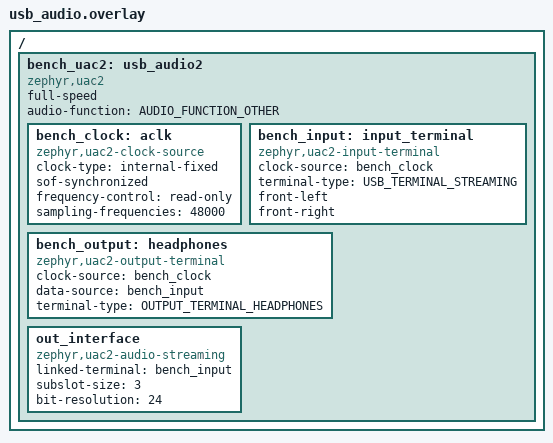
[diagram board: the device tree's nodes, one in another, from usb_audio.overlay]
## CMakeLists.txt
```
cmake_minimum_required(VERSION 3.20.0)
set(CMAKE_OBJECT_PATH_MAX 240)
find_package(Zephyr REQUIRED HINTS $ENV{ZEPHYR_BASE})
project(benchmark)
set(BENCH_ROLE tx CACHE STRING "tx, tx54 or rx")
set(BENCH_CODEC etsi CACHE STRING "etsi or google")
set(BENCH_FRAMES 200 CACHE STRING "Frames per case")
set(BENCH_SOAK_FRAMES 0 CACHE STRING "Frames per transport soak case")
set(BENCH_BITRATE 320000 CACHE STRING "Total stereo bitrate")
set(BENCH_PCM_BITS 16 CACHE STRING "LC3plus input precision; Opus sweeps 16 and 24")
set(BENCH_ASYNC_ONLY 0 CACHE STRING "Run nRF54 buffered radio cases only")
set(BENCH_USB 0 CACHE STRING "Receive PCM through USB Audio Class")
set(BENCH_OPTIMIZATIONS 0 CACHE STRING "Optimization experiment bit mask")
zephyr_get(BENCH_ROLE SYSBUILD)
zephyr_get(BENCH_CODEC SYSBUILD)
zephyr_get(BENCH_FRAMES SYSBUILD)
zephyr_get(BENCH_SOAK_FRAMES SYSBUILD)
zephyr_get(BENCH_BITRATE SYSBUILD)
zephyr_get(BENCH_PCM_BITS SYSBUILD)
zephyr_get(BENCH_ASYNC_ONLY SYSBUILD)
zephyr_get(BENCH_USB SYSBUILD)
zephyr_get(BENCH_OPTIMIZATIONS SYSBUILD)
target_compile_definitions(app PRIVATE BENCH_OPTIMIZATIONS=${BENCH_OPTIMIZATIONS})
math(EXPR BENCH_LEAN "${BENCH_OPTIMIZATIONS} & 1")
message(STATUS "Bench codec=${BENCH_CODEC} frames=${BENCH_FRAMES} soak=${BENCH_SOAK_FRAMES} bitrate=${BENCH_BITRATE} pcm_bits=${BENCH_PCM_BITS} LTO=${CONFIG_LTO}")
if(BENCH_CODEC MATCHES "-lto$" AND NOT CONFIG_LTO)
  message(FATAL_ERROR "Requested LTO was not enabled by Kconfig")
endif()
target_sources(app PRIVATE src/radio.c)
if(BENCH_USB)
  if(NOT BENCH_ROLE STREQUAL "tx" OR NOT BENCH_CODEC STREQUAL "google-custom-lto")
    message(FATAL_ERROR "USB benchmark requires tx/google-custom-lto")
  endif()
  target_sources(app PRIVATE src/main_usb.c src/usb_pcm.c src/usb_crc.c)
  target_compile_definitions(app PRIVATE BENCH_USB=1)
else()
  target_sources(app PRIVATE src/main.c)
endif()
target_compile_definitions(app PRIVATE BENCH_FRAMES=${BENCH_FRAMES} BENCH_SOAK_FRAMES=${BENCH_SOAK_FRAMES}
  BENCH_BITRATE=${BENCH_BITRATE} BENCH_PCM_BITS=${BENCH_PCM_BITS} BENCH_ASYNC_ONLY=${BENCH_ASYNC_ONLY})
if(BENCH_ROLE MATCHES "^tx")
  target_compile_definitions(app PRIVATE BENCH_TX=1)
  if(BENCH_ROLE STREQUAL "tx54")
    if(NOT BENCH_CODEC STREQUAL "google-lto")
      message(FATAL_ERROR "The tx54 benchmark currently supports google-lto")
    endif()
    target_compile_definitions(app PRIVATE BENCH_NRF54=1 BENCH_HAS_ASYNC=1)
    target_sources(app PRIVATE src/radio_async.c)
  endif()
  if(BENCH_CODEC MATCHES "^opus")
    include(opus.cmake)
  elseif(BENCH_CODEC MATCHES "^sbc")
    include(sbc.cmake)
  elseif(BENCH_CODEC MATCHES "^wavpack")
    include(wavpack.cmake)
  else()
    target_sources(app PRIVATE src/codec.c)
  endif()
  if(BENCH_CODEC MATCHES "^(opus|sbc|wavpack)")
    # Source list, precision and Cortex-M4 DSP options are in opus.cmake.
  elseif(BENCH_CODEC MATCHES "^etsi")
    set(REF ${CMAKE_CURRENT_SOURCE_DIR}/../third_party/lc3plus/fixed_point)
    file(GLOB CODEC_SOURCES ${REF}/*.c ${REF}/basic_op/*.c)
    list(FILTER CODEC_SOURCES EXCLUDE REGEX "/(codec_exe|ccConvert)\\.c$")
    # The desktop reference puts a 200 kB dummy scratch array on the stack.
    # Reuse our statically allocated scratch area during initialization.
    # This changes storage only; the codec arithmetic is unchanged.
    list(REMOVE_ITEM CODEC_SOURCES ${REF}/lc3plus.c)
    file(READ ${REF}/lc3plus.c PORTED_SOURCE)
    string(REPLACE "UWord8 tmp_scratch[LC3PLUS_ENC_MAX_USER_SYSTEM_SCRATCH_SIZE];"
      "extern unsigned char bench_codec_scratch[]; UWord8 *tmp_scratch = bench_codec_scratch;"
      PORTED_SOURCE "${PORTED_SOURCE}")
    file(WRITE ${CMAKE_CURRENT_BINARY_DIR}/lc3plus_port.c "${PORTED_SOURCE}")
    list(APPEND CODEC_SOURCES ${CMAKE_CURRENT_BINARY_DIR}/lc3plus_port.c)
    target_sources(app PRIVATE ${CODEC_SOURCES})
    target_sources(app PRIVATE src/ref_port.c)
    target_include_directories(app PRIVATE ${REF} ${REF}/basic_op)
    target_compile_definitions(app PRIVATE CODEC_ETSI=1 SUBSET_ALL DISABLE_HR_MODE WMOPS=0 DONT_COUNT_MEM NO_SCRATCH_STATS NDEBUG)
  else()
    set(REF ${CMAKE_CURRENT_SOURCE_DIR}/../third_party/liblc3)
    file(GLOB CODEC_SOURCES ${REF}/src/*.c)
    if(BENCH_CODEC STREQUAL "google-custom-lto")
      set(CUSTOM_DIR ${CMAKE_CURRENT_BINARY_DIR}/lc3-custom)
      set_property(DIRECTORY APPEND PROPERTY CMAKE_CONFIGURE_DEPENDS
        ${CMAKE_CURRENT_SOURCE_DIR}/../../tools/prepare-lc3-custom.py
        ${CMAKE_CURRENT_SOURCE_DIR}/../../tools/prepare-lc3-lite.py
        ${CMAKE_CURRENT_SOURCE_DIR}/src/custom_sns.inc
        ${CMAKE_CURRENT_SOURCE_DIR}/src/custom_spec.inc)
      execute_process(COMMAND ${PYTHON_EXECUTABLE}
        ${CMAKE_CURRENT_SOURCE_DIR}/../../tools/prepare-lc3-custom.py
        --source ${REF}/src --output ${CUSTOM_DIR}
        COMMAND_ERROR_IS_FATAL ANY)
      file(GLOB CODEC_SOURCES ${CUSTOM_DIR}/*.c)
      target_sources(app PRIVATE src/lc3_lite.c src/lc3_custom.c src/radio_async.c)
      target_include_directories(app PRIVATE src ${CUSTOM_DIR})
      target_compile_definitions(app PRIVATE CODEC_LC3_CUSTOM=1 CODEC_LC3_LITE=1 BENCH_HAS_ASYNC=1)
      if(NOT BENCH_LEAN)
        target_compile_definitions(app PRIVATE LC3_LITE_PROFILE=1)
      endif()
    elseif(BENCH_CODEC STREQUAL "google-lite-lto")
      set(LITE_DIR ${CMAKE_CURRENT_BINARY_DIR}/lc3-lite)
      set_property(DIRECTORY APPEND PROPERTY CMAKE_CONFIGURE_DEPENDS
        ${CMAKE_CURRENT_SOURCE_DIR}/../../tools/prepare-lc3-lite.py
        ${REF}/src/lc3.c ${REF}/src/tns.c ${REF}/src/spec.c)
      execute_process(COMMAND ${PYTHON_EXECUTABLE}
        ${CMAKE_CURRENT_SOURCE_DIR}/../../tools/prepare-lc3-lite.py
        --source ${REF}/src --output ${LITE_DIR}
        COMMAND_ERROR_IS_FATAL ANY)
      foreach(unit lc3 tns spec)
        list(REMOVE_ITEM CODEC_SOURCES ${REF}/src/${unit}.c)
        list(APPEND CODEC_SOURCES ${LITE_DIR}/${unit}.c)
      endforeach()
      target_sources(app PRIVATE src/lc3_lite.c src/radio_async.c)
      target_include_directories(app PRIVATE src ${REF}/src)
      target_compile_definitions(app PRIVATE CODEC_LC3_LITE=1 LC3_LITE_PROFILE=1 BENCH_HAS_ASYNC=1)
    endif()
    target_sources(app PRIVATE ${CODEC_SOURCES})
    target_include_directories(app PRIVATE ${REF}/include)
    target_compile_definitions(app PRIVATE LC3_PLUS=1 LC3_PLUS_HR=1)
  endif()
  set_source_files_properties(${CODEC_SOURCES} src/codec.c src/codec_opus.c src/codec_sbc.c src/codec_wavpack.c PROPERTIES COMPILE_OPTIONS "-O3;-std=c11")
  if(BENCH_CODEC MATCHES "^google.*-lto$")
    set_property(SOURCE ${CODEC_SOURCES} APPEND PROPERTY COMPILE_OPTIONS -ffast-math)
  endif()
  if(BENCH_CODEC STREQUAL "google-custom-lto")
    # Experiment with static-loop expansion in the existing transform kernel.
    # Retain the transform, window and coefficient tables.
    set_property(SOURCE ${CUSTOM_DIR}/mdct.c APPEND PROPERTY COMPILE_OPTIONS -funroll-loops)
  endif()
  target_link_libraries(app PRIVATE m)
elseif(BENCH_ROLE STREQUAL "rx")
  target_sources(app PRIVATE src/rx_ipc.c)
  target_compile_definitions(app PRIVATE BENCH_RX=1)
endif()
```

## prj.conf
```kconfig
CONFIG_ESB=y
CONFIG_ESB_MAX_PAYLOAD_LENGTH=252
CONFIG_ESB_TX_FIFO_SIZE=8
CONFIG_ESB_RX_FIFO_SIZE=16
CONFIG_CLOCK_CONTROL=y
CONFIG_USE_SEGGER_RTT=y
CONFIG_RTT_CONSOLE=y
CONFIG_UART_CONSOLE=n
CONFIG_SERIAL=n
CONFIG_CONSOLE=y
CONFIG_PRINTK=y
CONFIG_LOG=n
CONFIG_SEGGER_RTT_BUFFER_SIZE_UP=16384
CONFIG_SEGGER_RTT_INIT_MODE_ALWAYS=y
CONFIG_SEGGER_RTT_MODE_NO_BLOCK_SKIP=y
CONFIG_MAIN_STACK_SIZE=16384
CONFIG_SYSTEM_WORKQUEUE_STACK_SIZE=2048
CONFIG_SPEED_OPTIMIZATIONS=y
CONFIG_MINIMAL_LIBC=y
CONFIG_FPU=y
CONFIG_ASSERT=y
CONFIG_THREAD_STACK_INFO=y
CONFIG_INIT_STACKS=y
CONFIG_HW_STACK_PROTECTION=y
CONFIG_BOOT_BANNER=n
CONFIG_CRC=y

# The nRF5340 PRX forwards complete LC3-fast frames to the application core.
# The network-core RADIO/ESB ACK path remains independent of the decoder.
CONFIG_IPC_SERVICE=y
CONFIG_IPC_SERVICE_BACKEND_RPMSG=y
CONFIG_IPC_SERVICE_BACKEND_RPMSG_WQ_STACK_SIZE=2048
CONFIG_MBOX=y
CONFIG_HEAP_MEM_POOL_SIZE=2048
```

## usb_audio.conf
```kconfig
CONFIG_USB_DEVICE_STACK_NEXT=y
CONFIG_USBD_AUDIO2_CLASS=y
CONFIG_USBD_THREAD_STACK_SIZE=2048
CONFIG_UDC_NRF_THREAD_STACK_SIZE=1024
CONFIG_USBD_MAX_UDC_MSG=32
# Nano libc uses a byte-at-a-time memcpy on this toolchain. USB and the
# message/radio queues benefit from the full library's optimized copy routine.
CONFIG_NEWLIB_LIBC_NANO=n
```

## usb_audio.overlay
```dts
#include <dt-bindings/usb/audio.h>
/ {
    bench_uac2: usb_audio2 {
        compatible = "zephyr,uac2";
        status = "okay";
        full-speed;
        audio-function = <AUDIO_FUNCTION_OTHER>;
        bench_clock: aclk {
            compatible = "zephyr,uac2-clock-source";
            clock-type = "internal-fixed";
            sof-synchronized;
            frequency-control = "read-only";
            sampling-frequencies = <48000>;
        };
        bench_input: input_terminal {
            compatible = "zephyr,uac2-input-terminal";
            clock-source = <&bench_clock>;
            terminal-type = <USB_TERMINAL_STREAMING>;
            front-left;
            front-right;
        };
        bench_output: headphones {
            compatible = "zephyr,uac2-output-terminal";
            clock-source = <&bench_clock>;
            data-source = <&bench_input>;
            terminal-type = <OUTPUT_TERMINAL_HEADPHONES>;
        };
        out_interface {
            compatible = "zephyr,uac2-audio-streaming";
            linked-terminal = <&bench_input>;
            subslot-size = <3>;
            bit-resolution = <24>;
        };
    };
};
```

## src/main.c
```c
#include "bench.h"
#include <string.h>
#include <zephyr/sys/crc.h>
#include <cmsis_core.h>
#ifdef BENCH_RX
#include "rx_ipc.h"
#endif
#ifdef CODEC_LC3_LITE
#include "lc3_lite.h"
#endif
#ifdef CODEC_LC3_CUSTOM
#include "lc3_custom.h"
#endif
#ifdef BENCH_TX
static uint8_t encoded[MAX_FRAME];
static uint32_t timings[1024];
#ifdef CODEC_LC3_CUSTOM
static uint8_t vector_data[4][204];
static unsigned vector_bytes[4];
#endif
static uint32_t cycles_to_us(uint64_t cycles)
{
    return (uint32_t)(cycles * 1000000u / SystemCoreClock);
}
static int send_frame(uint32_t run, uint32_t seq, unsigned bytes,
                      bool async, uint64_t ready_us, uint64_t deadline_us)
{
    uint32_t crc = crc32_ieee(encoded, bytes);
    for (unsigned off=0; off<bytes; off+=CHUNK) {
        uint8_t packet[252];
        struct header h = {MAGIC, run, seq, crc, bytes, off, DATA, {0}};
        unsigned n = MIN(CHUNK, bytes-off);
        memcpy(packet, &h, sizeof(h)); memcpy(packet+sizeof(h), encoded+off, n);
        int rc;
#ifdef BENCH_HAS_ASYNC
        if (async) rc = radio_async_submit(packet, sizeof(h)+n, ready_us, deadline_us);
        else
#endif
            rc = radio_send(packet, sizeof(h)+n);
        if (rc) return rc;
    }
    return 0;
}
static void control(unsigned type, uint32_t run, uint32_t count)
{
    struct header h = {.magic=MAGIC, .run=run, .seq=count, .type=type};
    for (int i=0;i<3;i++) { if (!radio_send(&h, sizeof(h))) return; }
    printk("CONTROL_FAIL run=%u type=%u\n", run, type);
}
static void run_case(unsigned id, unsigned mode, unsigned frame_us, unsigned bitrate, unsigned nframes)
{
    /* mode 0: local encoding, 1: sequential RF, 2: synthetic RF only,
     * mode 3: encoding with concurrent RF at a fixed source cadence. */
    if (mode != 2) {
        int rc = codec_init(frame_us, bitrate);
        if (rc) { printk("CONFIG_ERROR id=%u rc=%d\n", id, rc); return; }
    }
    printk("BEGIN id=%u mode=%u frame_us=%u bitrate=%u frames=%u\n", id, mode, frame_us, bitrate, nframes);
    if (mode) control(START, id, nframes);
#ifdef BENCH_HAS_ASYNC
    struct radio_async_stats async_stats = {0};
    if (mode == 3 && radio_async_reset()) {
        printk("ASYNC_RESET_ERROR id=%u\n", id);
        return;
    }
#endif
    uint32_t ok0=tx_ok, fail0=tx_fail, ret0=tx_retries;
    uint64_t cycles=0, work=0, start=now_us(), due=start;
    uint64_t payload_bytes=0, slots=0;
    uint32_t payload_min=UINT32_MAX, payload_max=0, fragmented=0, data_packets=0;
#ifdef CODEC_SBC
    const unsigned period_num=8000, period_den=3;
#else
    const unsigned period_num=frame_us, period_den=1;
#endif
    uint32_t worst=0, worst_work=0, late=0, errors=0, send_errors=0, skips=0, timing_errors=0;
    uint64_t api_cycles=0;
    uint32_t api_max=0;
    uint32_t release_late_max=0;
    for (unsigned seq=0; seq<nframes; seq++) {
        uint64_t release=start+(uint64_t)seq*period_num/period_den;
        if (mode == 3) {
            uint64_t now=now_us();
            if (now<release) k_sleep(K_USEC(release-now));
            now=now_us();
            release_late_max=MAX(release_late_max,now>release ? now-release : 0);
        }
        unsigned bytes = bitrate*(uint64_t)frame_us/8000000;
        uint64_t t0=now_us();
        /* J-Link may clear trace enable on detach. Re-arm each measurement and
         * reject a case if a mid-frame probe change invalidates its counter. */
        CoreDebug->DEMCR |= CoreDebug_DEMCR_TRCENA_Msk;
        DWT->CTRL |= DWT_CTRL_CYCCNTENA_Msk;
        uint32_t c0=DWT->CYCCNT;
        if (mode != 2) {
            if (codec_encode(seq, encoded, &bytes)) errors++;
        } else {
            for (unsigned i=0;i<bytes;i++) encoded[i]=(uint8_t)(seq+i*29);
        }
        uint32_t dc=DWT->CYCCNT-c0;
        uint32_t measured_us=now_us()-t0;
        uint32_t cycle_us=cycles_to_us(dc);
        if (!dc || cycle_us+200<measured_us || measured_us+200<cycle_us) timing_errors++;
        if (mode != 2) { api_cycles+=codec_api_cycles; api_max=MAX(api_max,codec_api_cycles); }
        cycles+=dc; worst=MAX(worst, dc);
        payload_bytes+=bytes;
        payload_min=MIN(payload_min,bytes); payload_max=MAX(payload_max,bytes);
        fragmented+=bytes>CHUNK;
        data_packets+=DIV_ROUND_UP(bytes,CHUNK);
        if (seq<ARRAY_SIZE(timings)) timings[seq]=dc;
        /* Async ACK target: one further frame interval after the encode
         * deadline. Track its violations separately from producer cadence. */
        if (mode && send_frame(id,seq,bytes,mode==3,release,
                               release+2*period_num/period_den)) send_errors++;
#ifdef CODEC_LC3_CUSTOM
        if (seq<=75 && seq%25==0 && bytes<=204) {
            vector_bytes[seq/25]=bytes;
            memcpy(vector_data[seq/25],encoded,bytes);
        }
#endif
        uint32_t elapsed=now_us()-t0;
        work+=elapsed; worst_work=MAX(worst_work,elapsed);
        if (mode == 3) {
            due=start+(uint64_t)(seq+1)*period_num/period_den;
            if (now_us()>due) late++;
            /* Never shift the source phase or skip input to hide overload. */
        } else if (mode) {
            due=start+(++slots)*period_num/period_den;
            uint64_t now=now_us();
            if (now>due) {
                late++;
                /* Account for unsustainable source cadence; do not hide it
                 * by moving the next deadline forward without reporting. */
                while (start+(slots+1)*period_num/period_den<=now) { slots++; skips++; }
            } else k_sleep(K_USEC(due-now));
        }
    }
    uint64_t duration=now_us()-start;
#ifdef BENCH_HAS_ASYNC
    if (mode == 3) {
        int rc=radio_async_drain(&async_stats);
        if (rc) { printk("ASYNC_DRAIN_ERROR id=%u rc=%d\n",id,rc); return; }
        send_errors+=async_stats.errors;
        /* Include the last ACK; compare duration against nframes*period. */
        duration=now_us()-start;
    }
#endif
    if (mode) { control(END,id,nframes); k_sleep(K_MSEC(150)); }
    unsigned tcount=MIN(nframes, ARRAY_SIZE(timings));
    for(unsigned i=1;i<tcount;i++) { uint32_t x=timings[i]; unsigned j=i; while(j&&timings[j-1]>x){timings[j]=timings[j-1];j--;} timings[j]=x; }
    printk("RESULT id=%u mode=%u frame_us=%u bitrate=%u frames=%u enc_avg_us=%u enc_max_us=%u enc_p99_us=%u work_avg_us=%u work_max_us=%u late=%u skipped=%u codec_errors=%u send_errors=%u ack_ok=%u ack_fail=%u retries=%u elapsed_us=%llu",
       id,mode,frame_us,bitrate,nframes,cycles_to_us(cycles/nframes),cycles_to_us(worst),cycles_to_us(timings[(tcount-1)*99/100]),(uint32_t)(work/nframes),worst_work,late,skips,errors,send_errors,tx_ok-ok0,tx_fail-fail0,tx_retries-ret0,duration);
#ifdef CODEC_OPUS
    printk(" pcm_bits=%u complexity=%u",opus_pcm_bits,opus_complexity);
#else
    printk(" pcm_bits=%u",BENCH_PCM_BITS);
#endif
    printk(" api_avg_us=%u api_max_us=%u",cycles_to_us(api_cycles/nframes),cycles_to_us(api_max));
#ifdef CODEC_LC3_LITE
    printk(" lite_flags=%u",lc3_lite_flags);
#endif
#ifdef CODEC_LC3_CUSTOM
    printk(" sns_mode=%u rate_mode=%u tns=%u cap_channels=%u sns_clips=%u",
        custom_sns,custom_rate,custom_tns,custom_cap_frames,custom_sns_clips);
#endif
#ifdef CODEC_WAVPACK
    printk(" wavpack_fast=%u",wavpack_fast);
#endif
    printk(" timing_errors=%u payload_bytes=%llu period_num_us=%u period_den=%u",timing_errors,payload_bytes,period_num,period_den);
#ifdef BENCH_HAS_ASYNC
    if (mode == 3) printk(" radio_completed=%u radio_late=%u pending_peak=%u radio_service_avg_us=%u radio_service_max_us=%u ready_to_ack_avg_us=%u ready_to_ack_max_us=%u release_late_max_us=%u ack_budget_us=%u",
        async_stats.completed,async_stats.late,async_stats.peak_pending,
        (uint32_t)(async_stats.service_total_us/MAX(async_stats.completed,1)),async_stats.service_max_us,
        (uint32_t)(async_stats.latency_total_us/MAX(async_stats.completed,1)),async_stats.latency_max_us,
        release_late_max,2*period_num/period_den);
#endif
    printk(" payload_min=%u payload_max=%u fragmented_frames=%u data_packets=%u\n",payload_min,payload_max,fragmented,data_packets);
#ifdef CODEC_LC3_LITE
    /* Gain is nested inside spec; do not add it again to the stage total. */
    printk("PROFILE id=%u flags=%u",id,lc3_lite_flags);
    const char *names[] = {"attack","ltpf","mdct","energy","bw","sns","tns","spec","bits","gain"};
    for (unsigned i=0;i<PROF_COUNT;i++)
        printk(" %s_us=%u",names[i],cycles_to_us(lc3_lite_cycles[i]/nframes));
    printk("\n");
#endif
#ifdef CODEC_LC3_CUSTOM
    for (unsigned v=0;v<4 && v*25<nframes;v++) {
        printk("VECTOR id=%u seq=%u bytes=%u data=",id,v*25,vector_bytes[v]);
        for (unsigned b=0;b<vector_bytes[v];b++) printk("%02x",vector_data[v][b]);
        printk("\n");
    }
#endif
}
int main(void)
{
    CoreDebug->DEMCR |= CoreDebug_DEMCR_TRCENA_Msk;
    DWT->CYCCNT=0; DWT->CTRL |= DWT_CTRL_CYCCNTENA_Msk;
    int rc=radio_init();
    printk("BOOT TX codec=%s lto=%u cpu_hz=%u radio_init=%d frames=%u\n",codec_name(),IS_ENABLED(CONFIG_LTO),SystemCoreClock,rc,BENCH_FRAMES);
    if(rc) return rc;
    k_sleep(K_SECONDS(10));
    unsigned id=0;
#ifdef BENCH_NRF54
    const unsigned rates[] = {256000,320000};
#if BENCH_ASYNC_ONLY
    id=100;
    for (unsigned r=0;r<ARRAY_SIZE(rates);r++)
        run_case(++id,3,2500,rates[r],BENCH_FRAMES);
    if (BENCH_SOAK_FRAMES)
        for (unsigned r=0;r<ARRAY_SIZE(rates);r++)
            run_case(++id,3,2500,rates[r],BENCH_SOAK_FRAMES);
#else
    const unsigned frame_periods[] = {10000,5000,2500};
    for (unsigned r=0;r<ARRAY_SIZE(rates);r++)
        for (unsigned mode=0;mode<=1;mode++)
            for (unsigned f=0;f<ARRAY_SIZE(frame_periods);f++)
                run_case(++id,mode,frame_periods[f],rates[r],BENCH_FRAMES);
    if (BENCH_SOAK_FRAMES)
        for (unsigned r=0;r<ARRAY_SIZE(rates);r++)
            run_case(++id,1,2500,rates[r],BENCH_SOAK_FRAMES);
#endif
#elif defined(CODEC_LC3_CUSTOM)
    const unsigned rates[] = {256000,320000,400000,480000};
    const unsigned configs[][3] = {
        {0,0,1}, {1,0,1}, {2,0,1}, {3,0,1},
        {1,1,1}, {1,2,1}, {2,2,1}, {3,2,1},
        {1,0,0}, {1,2,0}, {3,0,0}, {3,2,0}
    };
    id=700;
#if !BENCH_ASYNC_ONLY
    for (unsigned c=0;c<ARRAY_SIZE(configs);c++)
        for (unsigned mode=0;mode<=3;mode+=3)
            for (unsigned r=0;r<ARRAY_SIZE(rates);r++) {
                lc3_custom_configure(configs[c][0],configs[c][1],configs[c][2]);
                run_case(++id,mode,2500,rates[r],BENCH_FRAMES);
            }
#endif
    if (BENCH_SOAK_FRAMES) {
        id=800;
        for (unsigned r=1;r<3;r++) {
            lc3_custom_configure(CUSTOM_SNS_COARSE,CUSTOM_VBR_ANALYTIC,0);
            run_case(++id,3,2500,rates[r],BENCH_SOAK_FRAMES);
        }
    }
#elif defined(CODEC_LC3_LITE)
    const unsigned rates[] = {256000,320000};
    const unsigned flags[] = {0,1,2,3,4,5,7};
    id=300;
    for (unsigned f=0;f<ARRAY_SIZE(flags);f++)
        for (unsigned mode=0;mode<=3;mode+=3)
            for (unsigned r=0;r<ARRAY_SIZE(rates);r++) {
                lc3_lite_set_flags(flags[f]);
                run_case(++id,mode,2500,rates[r],BENCH_FRAMES);
            }
    if (BENCH_SOAK_FRAMES)
        for (unsigned r=0;r<ARRAY_SIZE(rates);r++) {
            lc3_lite_set_flags(LITE_NO_LTPF);
            run_case(++id,3,2500,rates[r],BENCH_SOAK_FRAMES);
        }
#elif defined(CODEC_WAVPACK)
    const unsigned frame_periods[] = {5000,2500,1250};
    const unsigned rates[] = {256000,320000,384000};
    id=200;
    for (wavpack_fast=0;wavpack_fast<=1;wavpack_fast++)
        for (unsigned mode=0;mode<=3;mode+=3)
            for (unsigned r=0;r<ARRAY_SIZE(rates);r++)
                for (unsigned f=0;f<ARRAY_SIZE(frame_periods);f++)
                    run_case(++id,mode,frame_periods[f],rates[r],BENCH_FRAMES);
    wavpack_fast=1;
    if (BENCH_SOAK_FRAMES)
        for (unsigned r=0;r<ARRAY_SIZE(rates);r++)
            run_case(++id,3,2500,rates[r],BENCH_SOAK_FRAMES);
#elif defined(CODEC_SBC)
    for (unsigned mode=0;mode<=1;mode++) {
        run_case(++id,mode,2667,368000,BENCH_FRAMES);
        run_case(++id,mode,2667,372000,BENCH_FRAMES);
    }
    if (BENCH_SOAK_FRAMES) run_case(++id,1,2667,368000,BENCH_SOAK_FRAMES);
#elif defined(CODEC_OPUS)
    const unsigned frames[] = {10000,5000,2500};
    const unsigned complexities[] = {0,5,10};
    for (unsigned c=0;c<ARRAY_SIZE(complexities);c++) {
        opus_complexity=complexities[c];
        for (unsigned bits=16;bits<=24;bits+=8) {
            opus_pcm_bits=bits;
            for (unsigned mode=0;mode<=1;mode++)
                for (unsigned f=0;f<ARRAY_SIZE(frames);f++)
                    run_case(++id,mode,frames[f],BENCH_BITRATE,BENCH_FRAMES);
        }
    }
    if (BENCH_SOAK_FRAMES) {
        opus_complexity=0;
        for (unsigned bits=16;bits<=24;bits+=8) {
            opus_pcm_bits=bits;
            run_case(++id,1,2500,BENCH_BITRATE,BENCH_SOAK_FRAMES);
        }
    }
#else
    const unsigned frames[] = {10000,5000,2500,1250};
    for(unsigned mode=0;mode<3;mode++) {
        for(unsigned i=0;i<ARRAY_SIZE(frames);i++) run_case(++id,mode,frames[i],BENCH_BITRATE,BENCH_FRAMES);
        if (mode!=0 && BENCH_BITRATE==320000) run_case(++id,mode,5000,160000,BENCH_FRAMES);
        if (mode!=0 && BENCH_BITRATE==320000) run_case(++id,mode,5000,240000,BENCH_FRAMES);
    }
    if (BENCH_SOAK_FRAMES) {
        run_case(++id,2,2500,BENCH_BITRATE,BENCH_SOAK_FRAMES);
        run_case(++id,2,1250,BENCH_BITRATE,BENCH_SOAK_FRAMES);
    }
#endif
    printk("SUITE_DONE\n");
    while(1) { k_sleep(K_SECONDS(10)); printk("IDLE suite_done=1\n"); }
}
#else
static uint8_t frame[MAX_FRAME];
int main(void)
{
    int rc=radio_init();
    int ipc=rx_ipc_init();
    printk("BOOT RX radio_init=%d ipc=%d channel=40 rate=2M ack=1\n",rc,ipc);
    if(rc) return rc;
    uint32_t run=0, good=0, bad=0, packets=0, expected=0, seq=UINT32_MAX, crc=0;
    uint32_t ipc_send_errors=0;
    unsigned have=0, total=0;
    bool active=false;
    uint64_t start=0, last=now_us();
    while(1) {
        struct rx_packet p;
        if (k_msgq_get(&rx_queue,&p,K_SECONDS(2))) {
            printk("RX_ALIVE run=%u active=%u good=%u bad=%u overflow=%u\n",run,active,good,bad,rx_overflow);
            continue;
        }
        struct header h;
        if (p.length<sizeof(h)) continue;
        memcpy(&h,p.data,sizeof(h));
        if(h.magic!=MAGIC) continue;
        if(h.type==START) {
            if(active&&h.run==run) continue;
            run=h.run; good=bad=packets=ipc_send_errors=0; expected=h.seq;
            seq=UINT32_MAX; have=total=0; active=true; start=now_us();
            ipc_send_errors += rx_ipc_send_start(run, expected) != 0;
            printk("RX_BEGIN run=%u expected=%u\n",run,expected);
        } else if(h.type==END && h.run==run && active) {
            ipc_send_errors += rx_ipc_send_end(run, expected) != 0;
            struct rx_app_status app={0};
            int app_wait=rx_ipc_wait_status(&app,2000);
            printk("RX_SERVO run=%u updates=%u steps=%d error_us=%d peak_error_us=%d rejected=%u bias=%d\n",
                run,app.clock_updates,app.clock_steps,app.clock_error_us,
                app.clock_peak_error_us,app.clock_rejected,app.clock_test_bias);
            printk("RX_CLOCK run=%u dma_released=%u dma_span_us=%u dma_gap_max_us=%u arrival_span_us=%u pcm_slab_early=%u pcm_remaining=%u dac_irqs=%u\n",
                run,app.dma_released,app.dma_span_us,app.dma_gap_max_us,
                app.arrival_span_us,app.pcm_queue_early,app.pcm_remaining,app.dac_irqs);
            printk("RX_PLAYBACK run=%u pcm_slab_min=%u pcm_slab_max=%u pcm_slab_last=%u slot_bits=32 pcm_bits=24 prefill_frames=3\n",
                run,app.pcm_queue_min,app.pcm_queue_max,app.pcm_queue_last);
            printk("RX_RESULT run=%u expected=%u good=%u missing=%u bad=%u packets=%u overflow=%u ipc_send_errors=%u app_wait=%d app_decoded=%u app_plc=%u app_decode_errors=%u app_ipc_drops=%u app_queue_peak=%u app_decode_avg_us=%u app_decode_max_us=%u app_playback_late=%u app_i2s_blocks=%u app_i2s_errors=%u app_i2s_underruns=%u app_i2s_last_error=%d app_volume_updates=%u app_volume_last=%u app_accel_irqs=%u app_accel_work=%u app_i2c_attempts=%u app_i2c_failures=%u app_flags=%u elapsed_us=%llu\n",
                run,expected,good,expected-good,bad,packets,rx_overflow,ipc_send_errors,
                app_wait,app.decoded,app.plc_frames,app.decode_errors,app.ipc_drops,
                app.queue_peak,app.decode_avg_us,app.decode_max_us,app.playback_late,
                app.i2s_blocks,app.i2s_errors,app.i2s_underruns,app.i2s_last_error,app.volume_updates,
                app.volume_last,app.accel_irqs,app.accel_work,app.i2c_attempts,
                app.i2c_failures,app.status_flags,now_us()-start);
            active=false;
        } else if(h.type==DATA && active && h.run==run) {
            packets++;
            unsigned n=p.length-sizeof(h);
            if(h.bytes>MAX_FRAME||h.offset+n>h.bytes||h.seq>=expected) { bad++; continue; }
            if(h.seq!=seq) { seq=h.seq; have=0; total=h.bytes; crc=h.crc; }
            if(h.offset!=have||h.bytes!=total||h.crc!=crc) { bad++; continue; }
            memcpy(frame+have,p.data+sizeof(h),n); have+=n;
            if(have==total) {
                if(crc32_ieee(frame,total)==crc) {
                    good++;
                    ipc_send_errors += rx_ipc_send_frame(run, h.seq, frame, total, crc) != 0;
                } else bad++;
            }
        } else if(h.type==VOLUME && active && h.run==run) {
            ipc_send_errors += rx_ipc_send_volume(run, h.seq, h.bytes) != 0;
        }
        if(now_us()-last>5000000) { last=now_us(); printk("RX_PROGRESS run=%u good=%u packets=%u\n",run,good,packets); }
    }
}
#endif
```

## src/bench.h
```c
#pragma once
#include <stdint.h>
#include <zephyr/kernel.h>
#include "bench_opts.h"
#define MAGIC 0x4c433350u
#define CHUNK 224
#define MAX_FRAME 4096
/* Both MCUs are little endian. Fixed-width header is 24 bytes. */
struct header {
    uint32_t magic, run, seq, crc;
    uint16_t bytes, offset;
    uint8_t type, reserved[3];
};
BUILD_ASSERT(sizeof(struct header) == 24);
enum { START = 1, DATA = 2, END = 3, VOLUME = 4 };
struct rx_packet { uint16_t length; uint8_t data[252]; };
extern struct k_msgq rx_queue;
extern uint32_t rx_overflow;
int radio_init(void);
int radio_send(const void *data, unsigned len);
#ifdef BENCH_HAS_ASYNC
/* One radio worker owns blocking ESB calls while the main thread encodes.
 * The bounded queue owns a copy of each payload until its ACK or failure. */
struct radio_async_stats {
    uint32_t completed, errors, late, peak_pending;
    uint32_t service_max_us, latency_max_us;
    uint64_t service_total_us, latency_total_us;
};
int radio_async_reset(void);
int radio_async_submit(const void *data, unsigned len, uint64_t ready_us,
                       uint64_t deadline_us);
int radio_async_drain(struct radio_async_stats *stats);
#if OPT_TRANSPORT
/* Ownership transfers to commit(), including its error paths. The worker
 * releases the packet only after radio_send() has finished using it. */
struct radio_owned_packet {
    uint64_t ready_us, deadline_us;
    uint16_t length;
    uint8_t data[252];
};
struct radio_owned_packet *radio_async_acquire(void);
void radio_async_cancel(struct radio_owned_packet *packet);
int radio_async_commit(struct radio_owned_packet *packet);
uint32_t bench_crc32(const uint8_t *data, unsigned length);
#endif
#endif
extern uint32_t tx_ok, tx_fail, tx_retries;
int codec_init(unsigned frame_us, unsigned bitrate);
int codec_encode(unsigned sequence, uint8_t *out, unsigned *bytes);
const char *codec_name(void);
extern uint32_t codec_api_cycles;
#ifdef CODEC_WAVPACK
extern unsigned wavpack_fast;
#endif
#ifdef CODEC_OPUS
extern unsigned opus_pcm_bits, opus_complexity;
#endif
static inline uint64_t now_us(void) { return k_ticks_to_us_floor64(k_uptime_ticks()); }
```

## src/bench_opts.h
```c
#pragma once
/* Independent, reproducible experiments; zero retains the previous build. */
#ifndef BENCH_OPTIMIZATIONS
#define BENCH_OPTIMIZATIONS 0
#endif
#define OPT_LEAN       (BENCH_OPTIMIZATIONS & 1)
#define OPT_SNS        (BENCH_OPTIMIZATIONS & 2)
#define OPT_SPEC       (BENCH_OPTIMIZATIONS & 4)
#define OPT_TRANSPORT  (BENCH_OPTIMIZATIONS & 8)
#define OPT_MDCT       (BENCH_OPTIMIZATIONS & 16)
#define OPT_RAM        (BENCH_OPTIMIZATIONS & 32)
#if OPT_RAM && defined(__ZEPHYR__)
#include <zephyr/toolchain.h>
#define CUSTOM_RAM __ramfunc
#else
#define CUSTOM_RAM
#endif
```

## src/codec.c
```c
#include "bench.h"
#include <string.h>
#include <math.h>
#include <cmsis_core.h>
#ifdef CODEC_LC3_LITE
#include "lc3_lite.h"
#endif
#ifdef CODEC_LC3_CUSTOM
#include "lc3_custom.h"
BUILD_ASSERT(BENCH_PCM_BITS == 24);
static unsigned custom_bitrate;
#endif
#if CODEC_ETSI
#include <lc3plus.h>
static uint8_t state[LC3PLUS_ENC_MAX_SIZE] __aligned(8);
uint8_t bench_codec_scratch[LC3PLUS_ENC_MAX_SCRATCH_SIZE + 4096] __aligned(8);
#define scratch_mem bench_codec_scratch
static LC3PLUS_Enc *enc = (LC3PLUS_Enc *)state;
static lc3_scratch_t scratch;
#else
#include <lc3.h>
static lc3_encoder_mem_48k_t state[2];
static lc3_encoder_t enc[2];
static unsigned channel_bytes;
#endif
static unsigned samples;
static int16_t pcm[2][480], tone[2][480];
static int32_t pcm24[2][480];
static uint32_t rng = 0x48125340;
uint32_t codec_api_cycles;
#ifdef BENCH_USB
/* Let the existing codec loader consume packed interleaved PCM directly.
 * Same sample values and rate allocation as the synthetic benchmark. */
int codec_encode_usb(unsigned sequence, const uint8_t *input,
                     uint8_t *out, unsigned *bytes)
{
    uint32_t start=DWT->CYCCNT;
    unsigned offset=0;
    for (unsigned ch=0;ch<2;ch++) {
        uint64_t block=(uint64_t)sequence+ch;
        int target=(block+1)*custom_bitrate/6400-block*custom_bitrate/6400;
        int rc=lc3_custom_encode(enc[ch],LC3_PCM_FORMAT_S24_3LE,input+3*ch,2,
                                target,out+offset,CUSTOM_MAX_CHANNEL);
        if(rc<0) { codec_api_cycles=DWT->CYCCNT-start; return rc; }
        offset+=rc;
    }
    codec_api_cycles=DWT->CYCCNT-start;
    *bytes=offset;
    return 0;
}
#endif
BUILD_ASSERT(BENCH_PCM_BITS == 16 || BENCH_PCM_BITS == 24);
const char *codec_name(void) {
#if CODEC_ETSI
    return "ETSI-1.9.2-fixed-TS1.7.1";
#elif defined(CODEC_LC3_CUSTOM)
    return "Google-8e1e722-CUSTOM-SNS-VBR-v1";
#elif defined(CODEC_LC3_LITE)
    return "Google-8e1e722-LC3plus-experimental-lite";
#else
    return "Google-8e1e722-LC3plus";
#endif
}
int codec_init(unsigned frame_us, unsigned bitrate)
{
    samples = frame_us * 48 / 1000;
#ifdef CODEC_LC3_CUSTOM
    custom_bitrate=bitrate;
#endif
    rng = 0x48125340;
    for (unsigned ch=0; ch<2; ch++) for (unsigned i=0; i<480; i++)
        tone[ch][i] = (int16_t)(12000.f * sinf(6.283185307f * (ch ? 17 : 10) * i / 480.f));
#if CODEC_ETSI
    int32_t scratch_size = 0;
    int rc = lc3plus_enc_init(enc, 48000, 2, NULL, &scratch_size);
    if (!rc) rc = lc3plus_enc_set_frame_dms(enc, (LC3PLUS_FrameDuration)(frame_us / 1250));
    if (!rc) rc = lc3plus_enc_set_bitrate(enc, bitrate);
    int required = scratch_size;
    printk("MEM state=%d scratch=%d allocated=%u init=%d\n", lc3plus_enc_get_size(48000, 2), required, (unsigned)sizeof(scratch_mem), rc);
    if (required > sizeof(scratch_mem)) return -ENOMEM;
    scratch = (lc3_scratch_t)scratch_mem;
    return rc;
#else
    if (frame_us < 2500) return -ENOTSUP;
    channel_bytes = bitrate * (uint64_t)frame_us / 16000000;
    for (unsigned ch=0; ch<2; ch++) {
        enc[ch] = lc3_setup_encoder(frame_us, 48000, 48000, &state[ch]);
        if (!enc[ch]) return -EINVAL;
#ifdef CODEC_LC3_LITE
        if (lc3_lite_flags & LITE_NO_LTPF) lc3_encoder_disable_ltpf(enc[ch]);
#endif
    }
    printk("MEM state=%u\n", 2*lc3_encoder_size(frame_us, 48000));
    return 0;
#endif
}
int codec_encode(unsigned sequence, uint8_t *out, unsigned *bytes)
{
    /* Deterministic 4-part content: tones, noise, silence, transient mixture.
     * DWT timing includes this small PCM generation overhead. */
    for (unsigned ch=0; ch<2; ch++) for (unsigned i=0; i<samples; i++) {
        rng ^= rng << 13; rng ^= rng >> 17; rng ^= rng << 5;
        unsigned phase = (sequence / 25) % 4;
        int16_t x = tone[ch][(sequence * samples + i) % 480];
        x = phase == 0 ? x : phase == 1 ? (int16_t)rng / 2 : phase == 2 ? 0 : ((sequence+i)%7 == 0 ? (int16_t)rng : x);
        pcm[ch][i] = x;
        pcm24[ch][i] = (int32_t)x * 256 + (phase == 2 ? 0 : (rng & 255));
    }
#if CODEC_ETSI
    int16_t *p[2] = {pcm[0], pcm[1]};
    int32_t *p24[2] = {pcm24[0], pcm24[1]};
    int n = 0;
    uint32_t start = DWT->CYCCNT;
    int rc = BENCH_PCM_BITS == 24 ? lc3plus_enc24(enc, p24, out, &n, scratch)
                                : lc3plus_enc16(enc, p, out, &n, scratch);
    codec_api_cycles = DWT->CYCCNT - start;
    *bytes = n;
    return rc;
#else
    uint32_t start = DWT->CYCCNT;
#ifdef CODEC_LC3_CUSTOM
    unsigned offset=0;
#endif
    for (unsigned ch=0; ch<2; ch++) {
#ifdef CODEC_LC3_CUSTOM
        /* Alternate fractional byte allocation without losing the 400 kb/s
         * target to integer division; channel headers count against bitrate. */
        uint64_t block=(uint64_t)sequence+ch;
        int target=(block+1)*custom_bitrate/6400-block*custom_bitrate/6400;
        int rc=lc3_custom_encode(enc[ch],LC3_PCM_FORMAT_S24,pcm24[ch],1,
                                target,out+offset,CUSTOM_MAX_CHANNEL);
        if (rc<0) { codec_api_cycles=DWT->CYCCNT-start; return rc; }
        offset+=rc;
#else
        int rc = lc3_encode(enc[ch], BENCH_PCM_BITS == 24 ? LC3_PCM_FORMAT_S24 : LC3_PCM_FORMAT_S16,
                            BENCH_PCM_BITS == 24 ? (const void *)pcm24[ch] : (const void *)pcm[ch],
                            1, channel_bytes, out+ch*channel_bytes);
        if (rc) { codec_api_cycles = DWT->CYCCNT - start; return rc; }
#endif
    }
    codec_api_cycles = DWT->CYCCNT - start;
#ifdef CODEC_LC3_CUSTOM
    *bytes=offset;
#else
    *bytes = channel_bytes * 2;
#endif
    return 0;
#endif
}
```

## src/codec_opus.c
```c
#include "bench.h"
#include <opus.h>
#include <cmsis_core.h>
#include <math.h>

static uint8_t state[98304] __aligned(8);
static OpusEncoder *enc = (OpusEncoder *)state;
static int16_t pcm16[960], tone[2][480];
static int32_t pcm24[960];
static unsigned samples, packet_bytes;
static uint32_t rng;
unsigned opus_pcm_bits = 16, opus_complexity = 10;
uint32_t codec_api_cycles;

const char *codec_name(void)
{
#if defined(FIXED_POINT) && defined(ENABLE_RES24)
    return "Opus-1.6.1-CELT-fixed-res24";
#elif defined(FIXED_POINT)
    return "Opus-1.6.1-CELT-fixed-res16";
#else
    return "Opus-1.6.1-CELT-float";
#endif
}

int codec_init(unsigned frame_us, unsigned bitrate)
{
    if (frame_us < 2500) return -ENOTSUP;
#if defined(FIXED_POINT) && !defined(ENABLE_RES24)
    /* Do not present the default fixed-point API's 24-to-16 conversion as
     * true 24-bit processing. That is measured in the RES24 build. */
    if (opus_pcm_bits == 24) return -ENOTSUP;
#endif
    samples = frame_us * 48 / 1000;
    packet_bytes = (uint64_t)bitrate * frame_us / 8000000;
    rng = 0x48125340; /* Identical source sequence for every precision/complexity. */
    for (unsigned ch=0; ch<2; ch++) for (unsigned i=0; i<480; i++)
        tone[ch][i] = (int16_t)(12000.f * sinf(6.283185307f * (ch ? 17 : 10) * i / 480.f));
    int size = opus_encoder_get_size(2);
    if (size <= 0 || size > sizeof(state)) return -ENOMEM;
    int rc = opus_encoder_init(enc, 48000, 2, OPUS_APPLICATION_RESTRICTED_LOWDELAY);
#define SET(x) do { if (!rc) rc = opus_encoder_ctl(enc, x); } while (0)
    SET(OPUS_SET_BITRATE(bitrate));
    SET(OPUS_SET_VBR(0));
    SET(OPUS_SET_COMPLEXITY(opus_complexity));
    SET(OPUS_SET_FORCE_CHANNELS(2));
    SET(OPUS_SET_BANDWIDTH(OPUS_BANDWIDTH_FULLBAND));
    SET(OPUS_SET_SIGNAL(OPUS_SIGNAL_MUSIC));
    SET(OPUS_SET_INBAND_FEC(0));
    SET(OPUS_SET_DTX(0));
    SET(OPUS_SET_PACKET_LOSS_PERC(0));
    SET(OPUS_SET_LSB_DEPTH(opus_pcm_bits));
    int lookahead=0;
    SET(OPUS_GET_LOOKAHEAD(&lookahead));
#undef SET
    printk("OPUS_CONFIG pcm_bits=%u complexity=%u cbr=1 stereo=1 bandwidth=fullband lookahead_samples=%d state=%d init=%d\n",
           opus_pcm_bits, opus_complexity, lookahead, size, rc);
    return rc;
}

int codec_encode(unsigned sequence, uint8_t *out, unsigned *bytes)
{
    /* Same four content classes as the LC3plus test. 24-bit input has genuine
     * nonzero low bits; the 16-bit signal is its quantized counterpart. */
    for (unsigned ch=0; ch<2; ch++) for (unsigned i=0; i<samples; i++) {
        rng ^= rng << 13; rng ^= rng >> 17; rng ^= rng << 5;
        unsigned phase = (sequence / 25) % 4;
        int16_t x = tone[ch][(sequence * samples + i) % 480];
        x = phase == 0 ? x : phase == 1 ? (int16_t)rng / 2 : phase == 2 ? 0 : ((sequence+i)%7 == 0 ? (int16_t)rng : x);
        pcm16[2*i+ch] = x;
        pcm24[2*i+ch] = (int32_t)x * 256 + (phase == 2 ? 0 : (rng & 255));
    }
    uint32_t start = DWT->CYCCNT;
    int n = opus_pcm_bits == 24 ? opus_encode24(enc, pcm24, samples, out, MAX_FRAME)
                               : opus_encode(enc, pcm16, samples, out, MAX_FRAME);
    codec_api_cycles = DWT->CYCCNT - start;
    *bytes = n > 0 ? n : 0;
    if (n < 0) return n;
    /* Validate constant bitrate, CELT ToC, stereo, duration and full bandwidth. */
    if (n != packet_bytes || !(out[0] & 0x80) || opus_packet_get_nb_channels(out) != 2 ||
        opus_packet_get_nb_samples(out, n, 48000) != samples ||
        opus_packet_get_bandwidth(out) != OPUS_BANDWIDTH_FULLBAND) return -EBADMSG;
    return 0;
}
```

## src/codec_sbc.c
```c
#include "bench.h"
#include <sbc.h>
#include <cmsis_core.h>
#include <math.h>

static sbc_t encoder;
static struct sbc_frame format;
static int16_t pcm[256], tones[2][480];
static uint32_t rng, rate;
uint32_t codec_api_cycles;

const char *codec_name(void) { return "Google-SBC-XQ-dual-16"; }

int codec_init(unsigned frame_us, unsigned bitrate)
{
    if (frame_us != 2667 || (bitrate != 368000 && bitrate != 372000) || BENCH_PCM_BITS != 16)
        return -EINVAL;
    rate = bitrate;
    rng = 0x48125340;
    sbc_reset(&encoder);
    format = (struct sbc_frame){.freq=SBC_FREQ_48K, .mode=SBC_MODE_DUAL_CHANNEL,
        .bam=SBC_BAM_LOUDNESS, .nblocks=16, .nsubbands=8, .bitpool=28};
    for (unsigned ch=0;ch<2;ch++) for(unsigned i=0;i<480;i++)
        tones[ch][i] = (int16_t)(12000.f*sinf(6.283185307f*(ch?17:10)*i/480.f));
    printk("SBC_CONFIG pcm_bits=16 samples=128 period_num_us=8000 period_den=3 mode=dual subbands=8 blocks=16 bitpool_min=%u bitpool_max=28 rate=%u\n",
        rate==368000?27:28,rate);
    return 0;
}

int codec_encode(unsigned sequence, uint8_t *out, unsigned *bytes)
{
    for(unsigned ch=0;ch<2;ch++) for(unsigned i=0;i<128;i++) {
        rng^=rng<<13; rng^=rng>>17; rng^=rng<<5;
        unsigned phase=(sequence/25)%4;
        int16_t x=tones[ch][(sequence*128+i)%480];
        pcm[2*i+ch]=phase==0?x:phase==1?(int16_t)rng/2:phase==2?0:((sequence+i)%7==0?(int16_t)rng:x);
    }
    format.bitpool=rate==368000 && sequence%3==0 ? 27:28;
    *bytes=sbc_get_frame_size(&format);
    uint32_t start=DWT->CYCCNT;
    int rc=sbc_encode(&encoder,pcm,2,pcm+1,2,&format,out,MAX_FRAME);
    codec_api_cycles=DWT->CYCCNT-start;
    struct sbc_frame parsed;
    if (rc || sbc_probe(out,&parsed) || parsed.bitpool!=format.bitpool ||
        parsed.mode!=format.mode || parsed.nblocks!=16 || parsed.nsubbands!=8 ||
        parsed.freq!=SBC_FREQ_48K || *bytes!=(format.bitpool==27?120:124)) return -EBADMSG;
    return 0;
}
```

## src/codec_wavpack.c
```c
#include "bench.h"
#include <cmsis_core.h>
#include <math.h>
#include <string.h>
#include <wavpack-stream.h>

static WavpackContext *encoder;
static unsigned samples, produced, blocks;
static uint8_t *output;
static int32_t pcm[480*2];
static int16_t tone[2][480];
static uint32_t rng;
uint32_t codec_api_cycles;
unsigned wavpack_fast;

static int block_output(void *id, void *data, int32_t count)
{
    ARG_UNUSED(id);
    if (count < 12 || produced+(unsigned)count > MAX_FRAME) return 0;
    memcpy(output+produced, data, count);
    produced+=count;
    blocks++;
    return 1;
}

const char *codec_name(void) { return "WavPack-stream-79ec9e1"; }

int codec_init(unsigned frame_us, unsigned bitrate)
{
    if (encoder) encoder=WavpackStreamCloseFile(encoder);
    samples=frame_us*48/1000;
    if (samples<50 || samples>480) return -EINVAL;
    rng=0x48125340;
    for (unsigned ch=0;ch<2;ch++) for (unsigned i=0;i<480;i++)
        tone[ch][i]=(int16_t)(12000.f*sinf(6.283185307f*(ch?17:10)*i/480.f));
    encoder=WavpackStreamOpenFileOutput(block_output, NULL, NULL);
    if (!encoder) return -ENOMEM;
    WavpackStreamConfig config={0};
    config.sample_rate=48000;
    config.num_channels=2;
    config.channel_mask=3;
    config.bits_per_sample=BENCH_PCM_BITS;
    config.bytes_per_sample=BENCH_PCM_BITS/8;
    config.block_samples=samples;
    config.bitrate=bitrate/1000.f;
    config.flags=CONFIG_HYBRID_FLAG|CONFIG_BITRATE_KBPS|(wavpack_fast?CONFIG_FAST_FLAG:0);
    if (!WavpackStreamSetConfiguration64(encoder,&config,-1,NULL) ||
        !WavpackStreamPackInit(encoder)) {
        printk("WAVPACK_INIT_ERROR %s\n",WavpackStreamGetErrorMessage(encoder));
        return -EINVAL;
    }
    printk("WAVPACK_CONFIG samples=%u bits=%u target_kbps=%u fast=%u correction=0\n",
           samples,BENCH_PCM_BITS,bitrate/1000,wavpack_fast);
    return 0;
}

int codec_encode(unsigned sequence, uint8_t *out, unsigned *bytes)
{
    for (unsigned ch=0;ch<2;ch++) for (unsigned i=0;i<samples;i++) {
        rng^=rng<<13; rng^=rng>>17; rng^=rng<<5;
        unsigned phase=(sequence/25)%4;
        int16_t x=tone[ch][(sequence*samples+i)%480];
        x=phase==0?x:phase==1?(int16_t)rng/2:phase==2?0:
            ((sequence+i)%7==0?(int16_t)rng:x);
        pcm[i*2+ch]=BENCH_PCM_BITS==24 ? (int32_t)x*256+(phase==2?0:(rng&255)) : x;
    }
    output=out; produced=blocks=0;
    uint32_t start=DWT->CYCCNT;
    int ok=WavpackStreamPackSamples(encoder,pcm,samples);
    codec_api_cycles=DWT->CYCCNT-start;
    *bytes=produced;
    /* Full fixed-size input blocks must emit immediately, without flushing
     * or resetting predictors between blocks. Include all codec metadata. */
    if (!ok || blocks!=1 || !produced) return -EIO;
    return 0;
}
```

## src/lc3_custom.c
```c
#include "lc3_custom.h"
#include <stddef.h>
unsigned custom_sns, custom_rate, custom_tns;
unsigned custom_nbytes, custom_cap_frames, custom_sns_clips;
void lc3_custom_configure(unsigned sns, unsigned rate, unsigned tns)
{
    custom_sns=sns; custom_rate=rate; custom_tns=tns;
    custom_nbytes=custom_cap_frames=custom_sns_clips=0;
    lc3_lite_set_flags(LITE_NO_LTPF | (tns ? 0 : LITE_NO_TNS));
}
int lc3_custom_encode(lc3_encoder_t enc, enum lc3_pcm_format fmt,
    const void *pcm, int stride, int target_bytes, void *out, int capacity)
{
    if (!enc || !pcm || !out || stride<1 || (unsigned)fmt>LC3_PCM_FORMAT_FLOAT ||
        target_bytes<22 || target_bytes>CUSTOM_MAX_CHANNEL ||
        capacity<CUSTOM_MAX_CHANNEL || custom_sns>3 || custom_rate>2 ||
        enc->dt!=LC3_DT_2M5 || enc->sr!=LC3_SRATE_48K) return -1;
    uint8_t *p=out;
    lc3_encoder_disable_ltpf(enc);
    custom_nbytes=target_bytes-2;
    int rc=lc3_encode(enc,fmt,pcm,stride,target_bytes-2,p+2);
    if (rc) return rc;
    p[0]=0xd0|custom_sns;
    p[1]=custom_nbytes;
    return custom_nbytes+2;
}
int lc3_custom_decode(lc3_decoder_t dec, const void *packet, int length,
    enum lc3_pcm_format fmt, void *pcm, int stride)
{
    if (!dec || !pcm || stride<1 || (unsigned)fmt>LC3_PCM_FORMAT_FLOAT ||
        dec->dt!=LC3_DT_2M5 || dec->sr!=LC3_SRATE_48K) return -1;
    if (!packet) return lc3_decode(dec,NULL,20,fmt,pcm,stride);
    const uint8_t *p=packet;
    if (length<22 || length>CUSTOM_MAX_CHANNEL || (p[0]&0xfc)!=0xd0 ||
        p[1]!=length-2) return -1;
    unsigned saved=custom_sns;
    custom_sns=p[0]&3;
    int rc=lc3_decode(dec,p+2,p[1],fmt,pcm,stride);
    custom_sns=saved;
    return rc;
}
```

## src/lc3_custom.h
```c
#pragma once
#include <lc3.h>
#include "lc3_lite.h"
/* Research format v1: one independently parseable 2-byte header per channel.
 * Not LC3/LC3plus wire compatible. Only 48 kHz, 2.5 ms standard mode is tested.
 * The benchmark is single-encoder-thread; these controls are not reentrant. */
enum { CUSTOM_SNS_STOCK, CUSTOM_SNS_COARSE, CUSTOM_SNS_UNITY, CUSTOM_SNS_SCALAR };
enum { CUSTOM_CBR, CUSTOM_VBR_SEARCH, CUSTOM_VBR_ANALYTIC };
#define CUSTOM_MAX_CHANNEL 102
extern unsigned custom_sns, custom_rate, custom_tns;
extern unsigned custom_nbytes, custom_cap_frames, custom_sns_clips;
void lc3_custom_configure(unsigned sns, unsigned rate, unsigned tns);
int lc3_custom_encode(lc3_encoder_t enc, enum lc3_pcm_format fmt,
    const void *pcm, int stride, int target_bytes, void *out, int capacity);
int lc3_custom_decode(lc3_decoder_t dec, const void *packet, int length,
    enum lc3_pcm_format fmt, void *pcm, int stride);
```

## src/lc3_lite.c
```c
#include "lc3_lite.h"
#include <string.h>
unsigned lc3_lite_flags;
uint64_t lc3_lite_cycles[PROF_COUNT];
void lc3_lite_set_flags(unsigned flags)
{
    lc3_lite_flags = flags;
    memset(lc3_lite_cycles, 0, sizeof(lc3_lite_cycles));
}
```

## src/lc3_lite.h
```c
#pragma once
#include <stdint.h>
/* Experimental encoder flags. The decoder and wire syntax are unchanged. */
enum { LITE_NO_LTPF=1, LITE_NO_TNS=2, LITE_NO_GAIN_REFINE=4 };
enum { PROF_ATTACK, PROF_LTPF, PROF_MDCT, PROF_ENERGY, PROF_BW,
       PROF_SNS, PROF_TNS, PROF_SPEC, PROF_BITS, PROF_GAIN, PROF_COUNT };
extern unsigned lc3_lite_flags;
extern uint64_t lc3_lite_cycles[PROF_COUNT];
void lc3_lite_set_flags(unsigned flags);
#ifdef LC3_LITE_PROFILE
#include <cmsis_core.h>
#define LITE_MEASURE(slot, statement) do { \
    uint32_t lite_start_ = DWT->CYCCNT; \
    statement; \
    lc3_lite_cycles[slot] += (uint32_t)(DWT->CYCCNT - lite_start_); \
} while (0)
#else
#define LITE_MEASURE(slot, statement) do { statement; } while (0)
#endif
```
